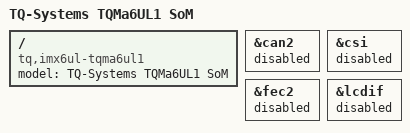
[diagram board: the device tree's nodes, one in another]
#include "imx6ul-tqma6ul2.dtsi"
/ {
	model = "TQ-Systems TQMa6UL1 SoM";
	compatible = "tq,imx6ul-tqma6ul1", "fsl,imx6ul";
};
&can2 {
	status = "disabled";
};
&csi {
	status = "disabled";
};
&fec2 {
	status = "disabled";
};
&lcdif {
	status = "disabled";
};
